# MSPM0G350X register map
Vendor: Texas Instruments; File version: This preliminary header file does not have a version number - build date: 2023-02-21 16:25:48
CPU: CM0 r0p1, little endian, MPU, no FPU, 3 interrupt priority bits
Registers are 32-bit, read-write, reset 0x0 unless marked. A register's access mark holds for its fields unless they carry their own. Offsets are from the block's base; [hi:lo] are bit positions; {n}, {i} and the like mark numbered series.

## GPIOB — PERIPHERALREGION
Base 0x400A2000
Same registers: GPIOA 0x400A0000
0x400 FSUB_0 — Subsciber Port 0
  [3:0] FSUB_0_CHANID — 0 = disconnected. 1-15 = connected to channelID = CHANID.
    0=FSUB_0_CHANID_UNCONNECTED (UNCONNECTED)
0x404 FSUB_1 — Subscriber Port 1
  [3:0] FSUB_1_CHANID — 0 = disconnected. 1-15 = connected to channelID = CHANID.
    0=FSUB_1_CHANID_UNCONNECTED (UNCONNECTED)
0x444 FPUB_0 — Publisher Port 0
  [3:0] FPUB_0_CHANID — 0 = disconnected. 1-15 = connected to channelID = CHANID.
    0=FPUB_0_CHANID_UNCONNECTED (UNCONNECTED)
0x448 FPUB_1 — Publisher Port 1
  [3:0] FPUB_1_CHANID — 0 = disconnected. 1-15 = connected to channelID = CHANID.
    0=FPUB_1_CHANID_UNCONNECTED (UNCONNECTED)
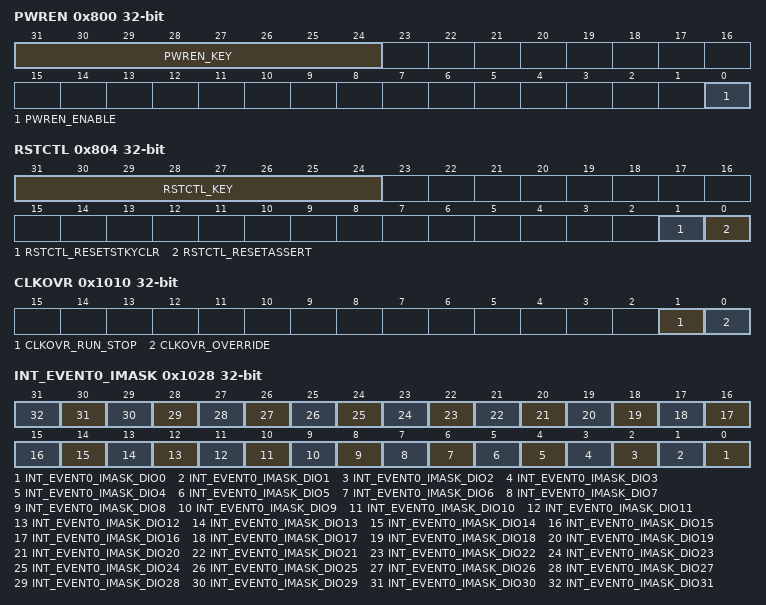
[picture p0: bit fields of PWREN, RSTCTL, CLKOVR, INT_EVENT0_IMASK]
0x800 PWREN — Power enable
  [31:24] PWREN_KEY wo — KEY to allow Power State Change
    38=PWREN_KEY_UNLOCK_W (_TO_UNLOCK_W_)
  [0] PWREN_ENABLE — Enable the power
    0=PWREN_ENABLE_DISABLE (DISABLE); 1=PWREN_ENABLE_ENABLE (ENABLE)
0x804 RSTCTL wo — Reset Control
  [31:24] RSTCTL_KEY — Unlock key
    177=RSTCTL_KEY_UNLOCK_W (_TO_UNLOCK_W_)
  [1] RSTCTL_RESETSTKYCLR — Clear the RESETSTKY bit in the STAT register
    0=RSTCTL_RESETSTKYCLR_NOP (NOP); 1=RSTCTL_RESETSTKYCLR_CLR (CLR)
  [0] RSTCTL_RESETASSERT — Assert reset to the peripheral
    0=RSTCTL_RESETASSERT_NOP (NOP); 1=RSTCTL_RESETASSERT_ASSERT (ASSERT)
0x814 STAT ro — Status Register
  [16] STAT_RESETSTKY — This bit indicates, if the peripheral was reset, since this bit was cleared by RESETSTKYCLR in the RSTCTL register
    0=STAT_RESETSTKY_NORES (NORES); 1=STAT_RESETSTKY_RESET (RESET)
0x1010 CLKOVR — Clock Override
  [1] CLKOVR_RUN_STOP — If [OVERRIDE] is enabled, this register is used to manually control the peripheral's clock request to the system
    0=CLKOVR_RUN_STOP_RUN (RUN); 1=CLKOVR_RUN_STOP_STOP (STOP)
  [0] CLKOVR_OVERRIDE — Unlocks the functionality of [RUN_STOP] to override the automatic peripheral clock request
    0=CLKOVR_OVERRIDE_DISABLED (DISABLED); 1=CLKOVR_OVERRIDE_ENABLED (ENABLED)
0x1018 PDBGCTL reset 0x1 — Peripheral Debug Control
  [0] PDBGCTL_FREE — Free run control
    0=PDBGCTL_FREE_STOP (STOP); 1=PDBGCTL_FREE_RUN (RUN)
0x1020 INT_EVENT0_IIDX ro — Interrupt index
  [7:0] INT_EVENT0_IIDX_STAT — Interrupt index status
    0=INT_EVENT0_IIDX_STAT_NO_INTR (NO_INTR); {v}=INT_EVENT0_IIDX_STAT_DIO{v-1} (DIO{v-1}) (v=1..32)
0x1028 INT_EVENT0_IMASK — Interrupt mask
  [n] INT_EVENT0_IMASK_DIO{n} (n=0..31) — DIO{n} event mask
    0=INT_EVENT0_IMASK_DIO{n}_CLR (CLR); 1=INT_EVENT0_IMASK_DIO{n}_SET (SET)
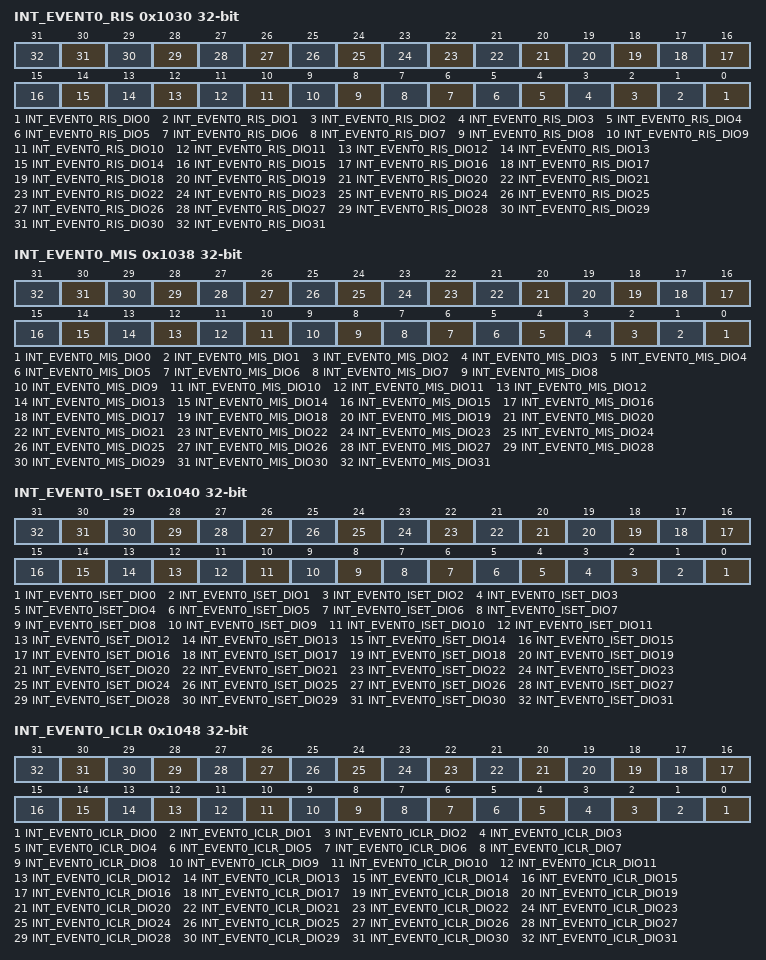
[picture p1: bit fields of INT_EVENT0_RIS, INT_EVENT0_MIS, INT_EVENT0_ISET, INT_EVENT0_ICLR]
0x1030 INT_EVENT0_RIS ro — Raw interrupt status
  [n] INT_EVENT0_RIS_DIO{n} (n=0..31) — DIO{n} event
    0=INT_EVENT0_RIS_DIO{n}_CLR (CLR); 1=INT_EVENT0_RIS_DIO{n}_SET (SET)
0x1038 INT_EVENT0_MIS ro — Masked interrupt status
  [n] INT_EVENT0_MIS_DIO{n} (n=0..31) — DIO{n} event
    0=INT_EVENT0_MIS_DIO{n}_CLR (CLR); 1=INT_EVENT0_MIS_DIO{n}_SET (SET)
0x1040 INT_EVENT0_ISET wo — Interrupt set
  [n] INT_EVENT0_ISET_DIO{n} (n=0..31) — DIO{n} event
    0=INT_EVENT0_ISET_DIO{n}_NO_EFFECT (NO_EFFECT); 1=INT_EVENT0_ISET_DIO{n}_SET (SET)
0x1048 INT_EVENT0_ICLR wo — Interrupt clear
  [n] INT_EVENT0_ICLR_DIO{n} (n=0..31) — DIO{n} event
    0=INT_EVENT0_ICLR_DIO{n}_NO_EFFECT (NO_EFFECT); 1=INT_EVENT0_ICLR_DIO{n}_CLR (CLR)
0x1050 INT_EVENT1_IIDX ro — Interrupt index
  [7:0] INT_EVENT1_IIDX_STAT — Interrupt index status
    0=INT_EVENT1_IIDX_STAT_NO_INTR (NO_INTR); {v}=INT_EVENT1_IIDX_STAT_DIO{v-1} (DIO{v-1}) (v=1..16)
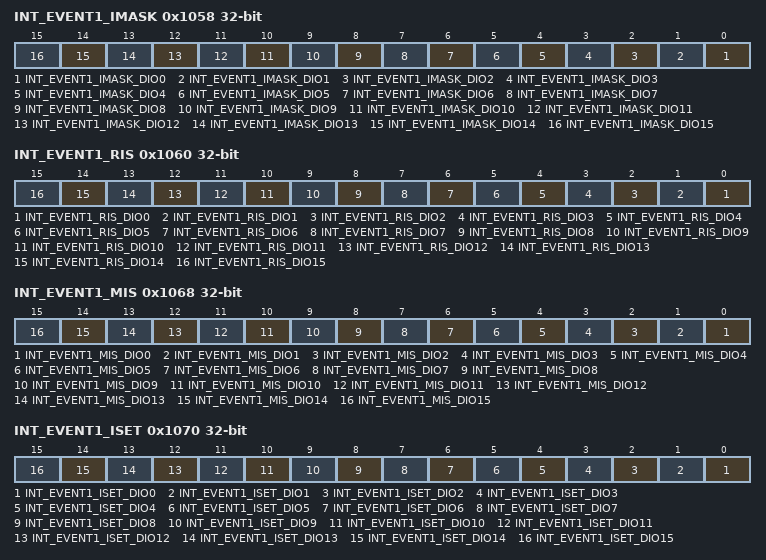
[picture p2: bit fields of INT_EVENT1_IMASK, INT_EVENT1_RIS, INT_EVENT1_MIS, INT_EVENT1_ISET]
0x1058 INT_EVENT1_IMASK — Interrupt mask
  [n] INT_EVENT1_IMASK_DIO{n} (n=0..15) — DIO{n} event mask
    0=INT_EVENT1_IMASK_DIO{n}_CLR (CLR); 1=INT_EVENT1_IMASK_DIO{n}_SET (SET)
0x1060 INT_EVENT1_RIS ro — Raw interrupt status
  [n] INT_EVENT1_RIS_DIO{n} (n=0..15) — DIO{n} event
    0=INT_EVENT1_RIS_DIO{n}_CLR (CLR); 1=INT_EVENT1_RIS_DIO{n}_SET (SET)
0x1068 INT_EVENT1_MIS ro — Masked interrupt status
  [n] INT_EVENT1_MIS_DIO{n} (n=0..15) — DIO{n} event
    0=INT_EVENT1_MIS_DIO{n}_CLR (CLR); 1=INT_EVENT1_MIS_DIO{n}_SET (SET)
0x1070 INT_EVENT1_ISET wo — Interrupt set
  [n] INT_EVENT1_ISET_DIO{n} (n=0..15) — DIO{n} event
    0=INT_EVENT1_ISET_DIO{n}_NO_EFFECT (NO_EFFECT); 1=INT_EVENT1_ISET_DIO{n}_SET (SET)
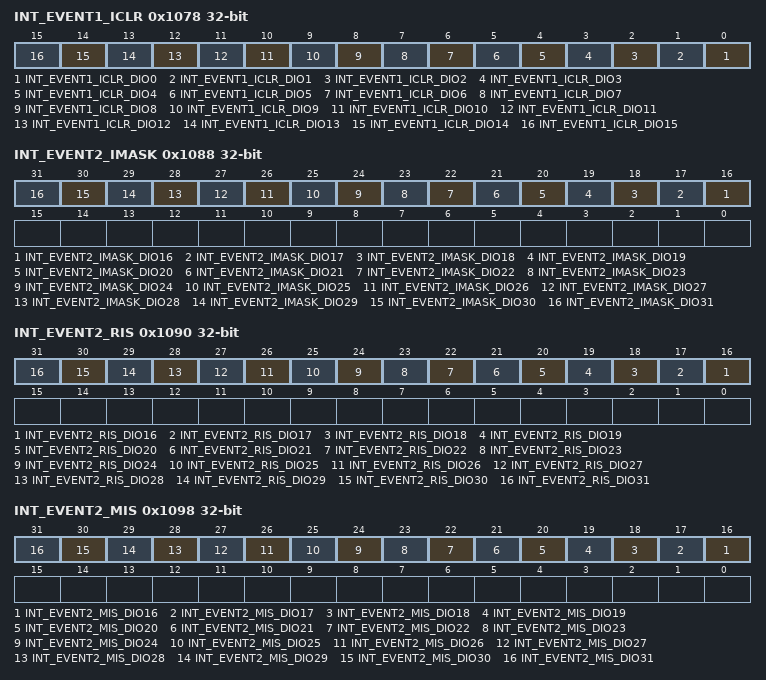
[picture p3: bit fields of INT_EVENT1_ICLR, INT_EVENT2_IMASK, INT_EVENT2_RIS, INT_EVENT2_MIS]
0x1078 INT_EVENT1_ICLR wo — Interrupt clear
  [n] INT_EVENT1_ICLR_DIO{n} (n=0..15) — DIO{n} event
    0=INT_EVENT1_ICLR_DIO{n}_NO_EFFECT (NO_EFFECT); 1=INT_EVENT1_ICLR_DIO{n}_CLR (CLR)
0x1080 INT_EVENT2_IIDX ro — Interrupt index
  [7:0] INT_EVENT2_IIDX_STAT — Interrupt index status
    0=INT_EVENT2_IIDX_STAT_NO_INTR (NO_INTR); {v}=INT_EVENT2_IIDX_STAT_DIO{v+15} (DIO{v+15}) (v=1..16)
0x1088 INT_EVENT2_IMASK — Interrupt mask
  [n] INT_EVENT2_IMASK_DIO{n} (n=16..31) — DIO{n} event mask
    0=INT_EVENT2_IMASK_DIO{n}_CLR (CLR); 1=INT_EVENT2_IMASK_DIO{n}_SET (SET)
0x1090 INT_EVENT2_RIS ro — Raw interrupt status
  [n] INT_EVENT2_RIS_DIO{n} (n=16..31) — DIO{n} event
    0=INT_EVENT2_RIS_DIO{n}_CLR (CLR); 1=INT_EVENT2_RIS_DIO{n}_SET (SET)
0x1098 INT_EVENT2_MIS ro — Masked interrupt status
  [n] INT_EVENT2_MIS_DIO{n} (n=16..31) — DIO{n} event
    0=INT_EVENT2_MIS_DIO{n}_CLR (CLR); 1=INT_EVENT2_MIS_DIO{n}_SET (SET)
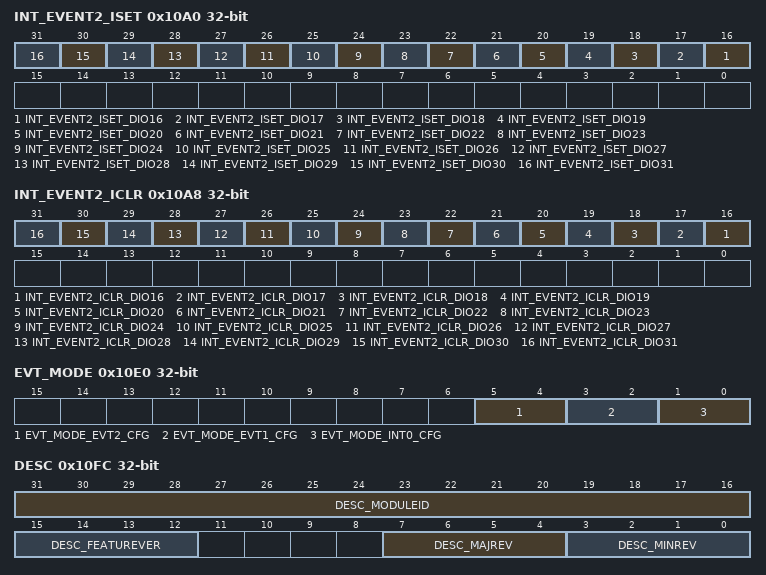
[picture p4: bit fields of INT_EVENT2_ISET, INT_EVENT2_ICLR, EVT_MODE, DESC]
0x10A0 INT_EVENT2_ISET wo — Interrupt set
  [n] INT_EVENT2_ISET_DIO{n} (n=16..31) — DIO{n} event
    0=INT_EVENT2_ISET_DIO{n}_NO_EFFECT (NO_EFFECT); 1=INT_EVENT2_ISET_DIO{n}_SET (SET)
0x10A8 INT_EVENT2_ICLR wo — Interrupt clear
  [n] INT_EVENT2_ICLR_DIO{n} (n=16..31) — DIO{n} event
    0=INT_EVENT2_ICLR_DIO{n}_NO_EFFECT (NO_EFFECT); 1=INT_EVENT2_ICLR_DIO{n}_CLR (CLR)
0x10E0 EVT_MODE — Event Mode
  [5:4] EVT_MODE_EVT2_CFG ro — Event line mode select for event corresponding to [IPSTANDARD.INT_EVENT2]
    0=EVT_MODE_EVT2_CFG_DISABLE (DISABLE); 1=EVT_MODE_EVT2_CFG_SOFTWARE (SOFTWARE); 2=EVT_MODE_EVT2_CFG_HARDWARE (HARDWARE)
  [3:2] EVT_MODE_EVT1_CFG ro — Event line mode select for event corresponding to [IPSTANDARD.INT_EVENT1]
    0=EVT_MODE_EVT1_CFG_DISABLE (DISABLE); 1=EVT_MODE_EVT1_CFG_SOFTWARE (SOFTWARE); 2=EVT_MODE_EVT1_CFG_HARDWARE (HARDWARE)
  [1:0] EVT_MODE_INT0_CFG ro — Event line mode select for event corresponding to [IPSTANDARD.INT_EVENT0]
    0=EVT_MODE_INT0_CFG_DISABLE (DISABLE); 1=EVT_MODE_INT0_CFG_SOFTWARE (SOFTWARE); 2=EVT_MODE_INT0_CFG_HARDWARE (HARDWARE)
0x10FC DESC ro — Module Description
  [31:16] DESC_MODULEID — Module identification contains a unique peripheral identification number. The assignments are maintained in a central database for all of the platform modules to ensure uniqueness.
  [15:12] DESC_FEATUREVER — Feature Set for the module *instance*
  [7:4] DESC_MAJREV — Major rev of the IP
  [3:0] DESC_MINREV — Minor rev of the IP
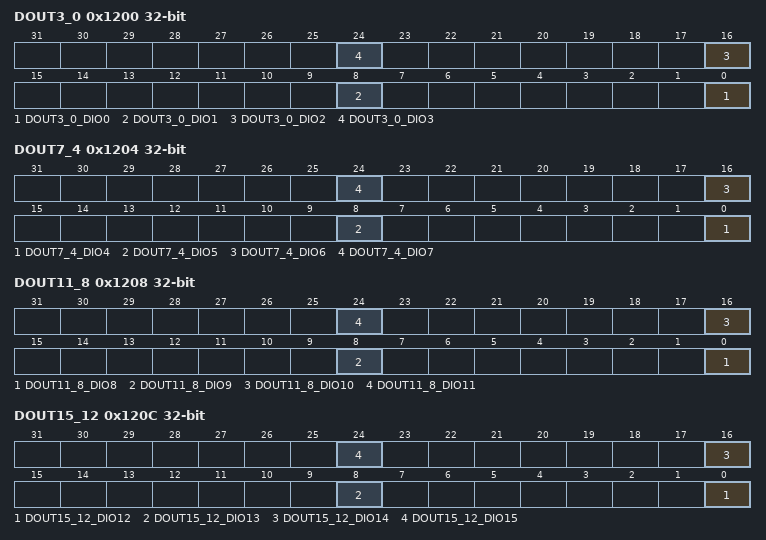
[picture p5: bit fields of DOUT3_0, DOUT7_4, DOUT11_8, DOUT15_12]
0x1200 DOUT3_0 wo — Data output 3 to 0
  [8n] DOUT3_0_DIO{n} (n=0..3) — This bit sets the value of the pin configured as DIO{n} when the output is enabled through DOE31_0 register.
    0=DOUT3_0_DIO{n}_ZERO (ZERO); 1=DOUT3_0_DIO{n}_ONE (ONE)
0x1204 DOUT7_4 wo — Data output 7 to 4
  [8n-32] DOUT7_4_DIO{n} (n=4..7) — This bit sets the value of the pin configured as DIO{n} when the output is enabled through DOE31_0 register.
    0=DOUT7_4_DIO{n}_ZERO (ZERO); 1=DOUT7_4_DIO{n}_ONE (ONE)
0x1208 DOUT11_8 wo — Data output 11 to 8
  [8n-64] DOUT11_8_DIO{n} (n=8..11) — This bit sets the value of the pin configured as DIO{n} when the output is enabled through DOE31_0 register.
    0=DOUT11_8_DIO{n}_ZERO (ZERO); 1=DOUT11_8_DIO{n}_ONE (ONE)
0x120C DOUT15_12 wo — Data output 15 to 12
  [8n-96] DOUT15_12_DIO{n} (n=12..15) — This bit sets the value of the pin configured as DIO{n} when the output is enabled through DOE31_0 register.
    0=DOUT15_12_DIO{n}_ZERO (ZERO); 1=DOUT15_12_DIO{n}_ONE (ONE)
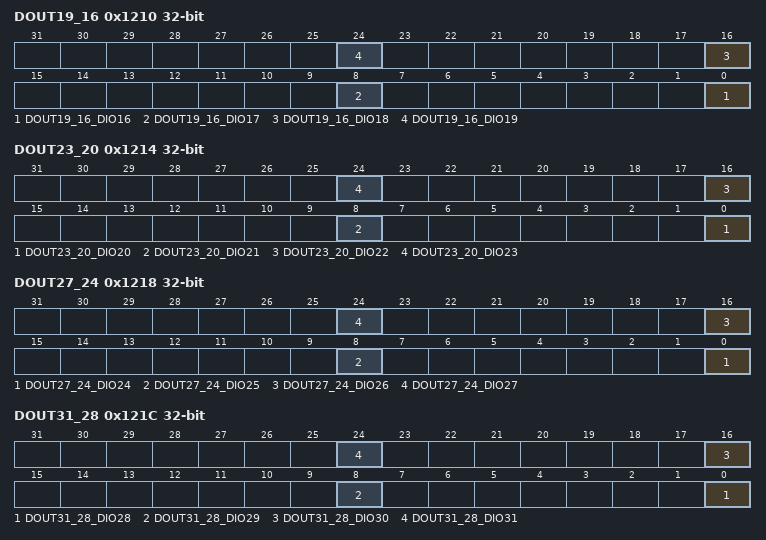
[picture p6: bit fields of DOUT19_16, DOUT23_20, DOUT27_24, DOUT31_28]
0x1210 DOUT19_16 wo — Data output 19 to 16
  [8n-128] DOUT19_16_DIO{n} (n=16..19) — This bit sets the value of the pin configured as DIO{n} when the output is enabled through DOE31_0 register.
    0=DOUT19_16_DIO{n}_ZERO (ZERO); 1=DOUT19_16_DIO{n}_ONE (ONE)
0x1214 DOUT23_20 wo — Data output 23 to 20
  [8n-160] DOUT23_20_DIO{n} (n=20..23) — This bit sets the value of the pin configured as DIO{n} when the output is enabled through DOE31_0 register.
    0=DOUT23_20_DIO{n}_ZERO (ZERO); 1=DOUT23_20_DIO{n}_ONE (ONE)
0x1218 DOUT27_24 wo — Data output 27 to 24
  [8n-192] DOUT27_24_DIO{n} (n=24..27) — This bit sets the value of the pin configured as DIO{n} when the output is enabled through DOE31_0 register.
    0=DOUT27_24_DIO{n}_ZERO (ZERO); 1=DOUT27_24_DIO{n}_ONE (ONE)
0x121C DOUT31_28 wo — Data output 31 to 28
  [8n-224] DOUT31_28_DIO{n} (n=28..31) — This bit sets the value of the pin configured as DIO{n} when the output is enabled through DOE31_0 register.
    0=DOUT31_28_DIO{n}_ZERO (ZERO); 1=DOUT31_28_DIO{n}_ONE (ONE)
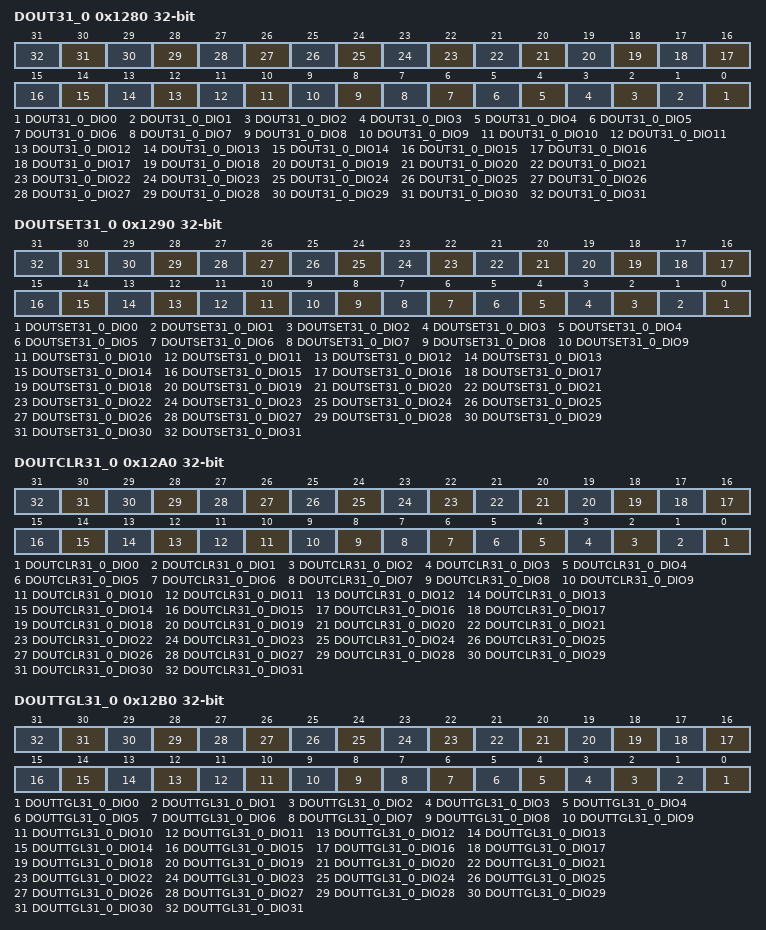
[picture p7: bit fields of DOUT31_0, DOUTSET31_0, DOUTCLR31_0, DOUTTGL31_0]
0x1280 DOUT31_0 — Data output 31 to 0
  [n] DOUT31_0_DIO{n} (n=0..31) — This bit sets the value of the pin configured as DIO{n} when the output is enabled through DOE31_0 register.
    0=DOUT31_0_DIO{n}_ZERO (ZERO); 1=DOUT31_0_DIO{n}_ONE (ONE)
0x1290 DOUTSET31_0 wo — Data output set 31 to 0
  [n] DOUTSET31_0_DIO{n} (n=0..31) — Writing 1 to this bit sets the DIO{n} bit in the DOUT31_0 register. Writing 0 has no effect.
    0=DOUTSET31_0_DIO{n}_NO_EFFECT (NO_EFFECT); 1=DOUTSET31_0_DIO{n}_SET (SET)
0x12A0 DOUTCLR31_0 wo — Data output clear 31 to 0
  [n] DOUTCLR31_0_DIO{n} (n=0..31) — Writing 1 to this bit clears the DIO{n} bit in the DOUT31_0 register. Writing 0 has no effect.
    0=DOUTCLR31_0_DIO{n}_NO_EFFECT (NO_EFFECT); 1=DOUTCLR31_0_DIO{n}_CLR (CLR)
0x12B0 DOUTTGL31_0 wo — Data output toggle 31 to 0
  [n] DOUTTGL31_0_DIO{n} (n=0..31) — This bit is used to toggle DIO{n} output.
    0=DOUTTGL31_0_DIO{n}_NO_EFFECT (NO_EFFECT); 1=DOUTTGL31_0_DIO{n}_TOGGLE (TOGGLE)
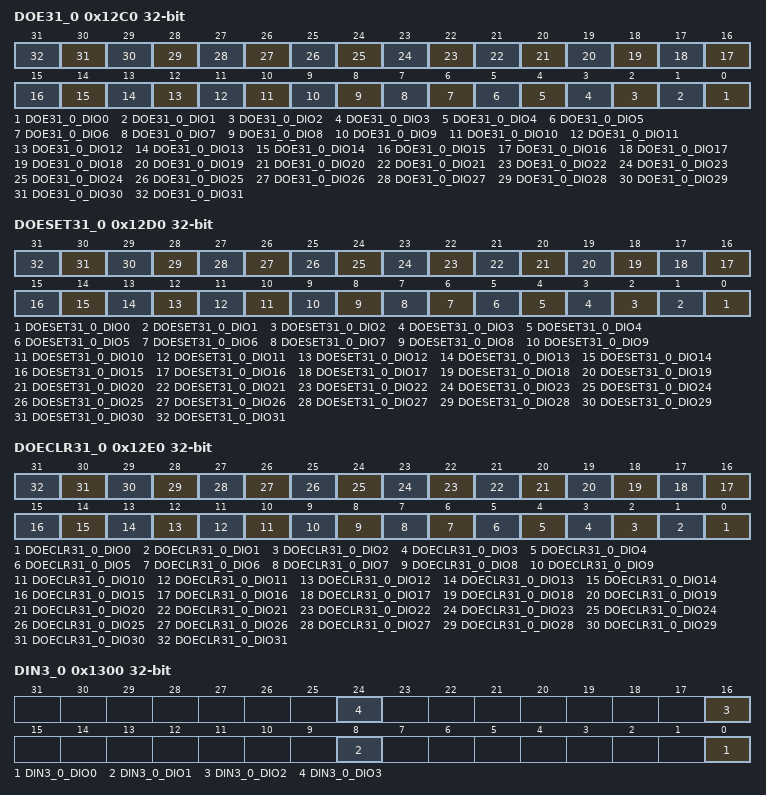
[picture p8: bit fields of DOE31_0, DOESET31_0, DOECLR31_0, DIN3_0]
0x12C0 DOE31_0 — Data output enable 31 to 0
  [n] DOE31_0_DIO{n} (n=0..31) — Enables data output for DIO{n}.
    0=DOE31_0_DIO{n}_DISABLE (DISABLE); 1=DOE31_0_DIO{n}_ENABLE (ENABLE)
0x12D0 DOESET31_0 wo — Data output enable set 31 to 0
  [n] DOESET31_0_DIO{n} (n=0..31) — Writing 1 to this bit sets the DIO{n} bit in the DOE31_0 register. Writing 0 has no effect.
    0=DOESET31_0_DIO{n}_NO_EFFECT (NO_EFFECT); 1=DOESET31_0_DIO{n}_SET (SET)
0x12E0 DOECLR31_0 wo — Data output enable clear 31 to 0
  [n] DOECLR31_0_DIO{n} (n=0..31) — Writing 1 to this bit clears the DIO{n} bit in the DOE31_0 register. Writing 0 has no effect.
    0=DOECLR31_0_DIO{n}_NO_EFFECT (NO_EFFECT); 1=DOECLR31_0_DIO{n}_CLR (CLR)
0x1300 DIN3_0 ro — Data input 3 to 0
  [8n] DIN3_0_DIO{n} (n=0..3) — This bit reads the data input value of DIO{n}.
    0=DIN3_0_DIO{n}_ZERO (ZERO); 1=DIN3_0_DIO{n}_ONE (ONE)
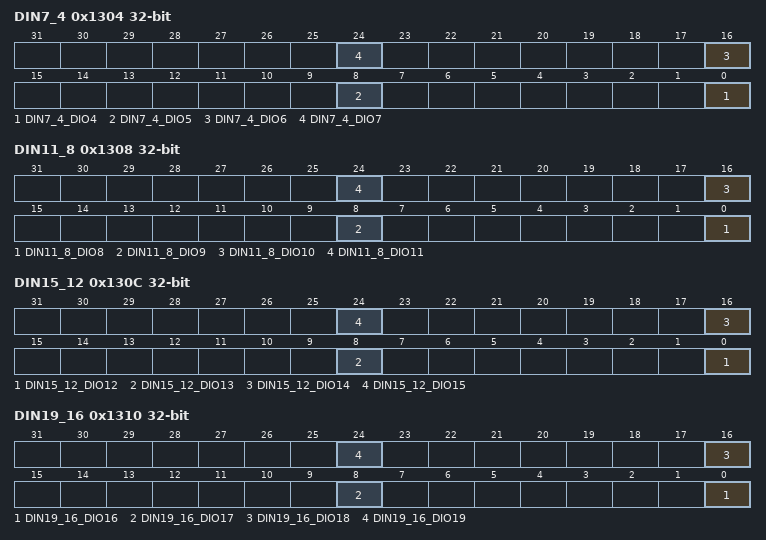
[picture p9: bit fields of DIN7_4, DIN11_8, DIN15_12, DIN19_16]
0x1304 DIN7_4 ro — Data input 7 to 4
  [8n-32] DIN7_4_DIO{n} (n=4..7) — This bit reads the data input value of DIO{n}.
    0=DIN7_4_DIO{n}_ZERO (ZERO); 1=DIN7_4_DIO{n}_ONE (ONE)
0x1308 DIN11_8 ro — Data input 11 to 8
  [8n-64] DIN11_8_DIO{n} (n=8..11) — This bit reads the data input value of DIO{n}.
    0=DIN11_8_DIO{n}_ZERO (ZERO); 1=DIN11_8_DIO{n}_ONE (ONE)
0x130C DIN15_12 ro — Data input 15 to 12
  [8n-96] DIN15_12_DIO{n} (n=12..15) — This bit reads the data input value of DIO{n}.
    0=DIN15_12_DIO{n}_ZERO (ZERO); 1=DIN15_12_DIO{n}_ONE (ONE)
0x1310 DIN19_16 ro — Data input 19 to 16
  [8n-128] DIN19_16_DIO{n} (n=16..19) — This bit reads the data input value of DIO{n}.
    0=DIN19_16_DIO{n}_ZERO (ZERO); 1=DIN19_16_DIO{n}_ONE (ONE)
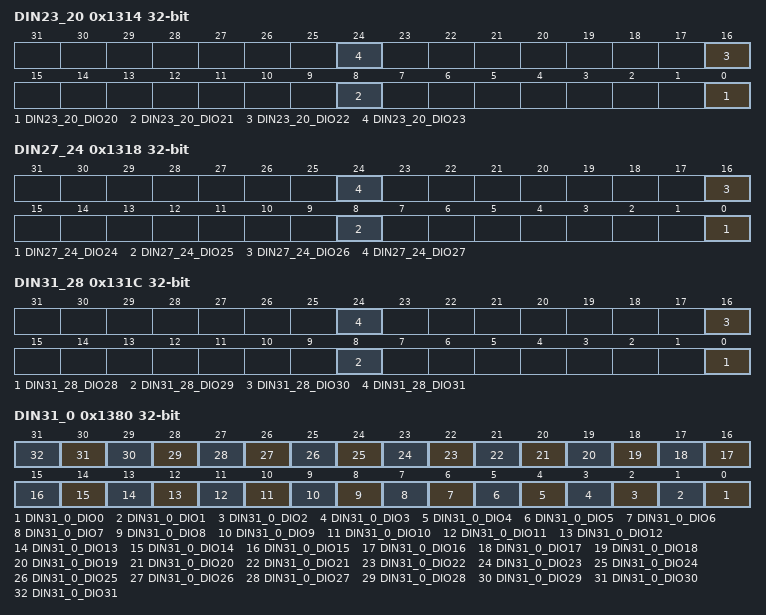
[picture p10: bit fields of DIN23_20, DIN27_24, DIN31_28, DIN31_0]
0x1314 DIN23_20 ro — Data input 23 to 20
  [8n-160] DIN23_20_DIO{n} (n=20..23) — This bit reads the data input value of DIO{n}.
    0=DIN23_20_DIO{n}_ZERO (ZERO); 1=DIN23_20_DIO{n}_ONE (ONE)
0x1318 DIN27_24 ro — Data input 27 to 24
  [8n-192] DIN27_24_DIO{n} (n=24..27) — This bit reads the data input value of DIO{n}.
    0=DIN27_24_DIO{n}_ZERO (ZERO); 1=DIN27_24_DIO{n}_ONE (ONE)
0x131C DIN31_28 ro — Data input 31 to 28
  [8n-224] DIN31_28_DIO{n} (n=28..31) — This bit reads the data input value of DIO{n}.
    0=DIN31_28_DIO{n}_ZERO (ZERO); 1=DIN31_28_DIO{n}_ONE (ONE)
0x1380 DIN31_0 ro — Data input 31 to 0
  [n] DIN31_0_DIO{n} (n=0..31) — This bit reads the data input value of DIO{n}.
    0=DIN31_0_DIO{n}_ZERO (ZERO); 1=DIN31_0_DIO{n}_ONE (ONE)
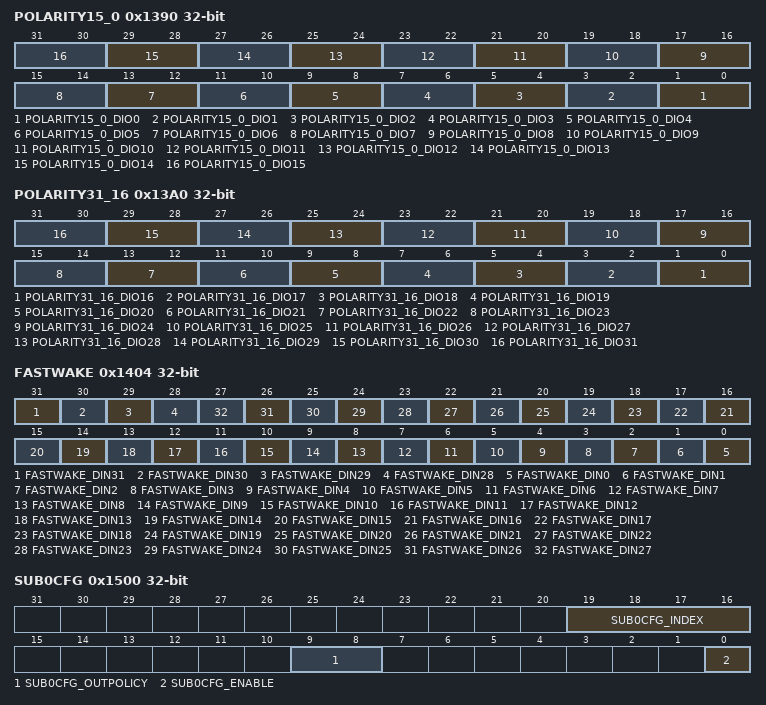
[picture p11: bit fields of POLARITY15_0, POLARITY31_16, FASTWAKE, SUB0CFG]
0x1390 POLARITY15_0 — Polarity 15 to 0
  [2n+1:2n] POLARITY15_0_DIO{n} (n=0..15) — Enables and configures edge detection polarity for DIO{n}.
    0=POLARITY15_0_DIO{n}_DISABLE (DISABLE); 1=POLARITY15_0_DIO{n}_RISE (RISE); 2=POLARITY15_0_DIO{n}_FALL (FALL); 3=POLARITY15_0_DIO{n}_RISE_FALL (RISE_FALL)
0x13A0 POLARITY31_16 — Polarity 31 to 16
  [2n-31:2n-32] POLARITY31_16_DIO{n} (n=16..31) — Enables and configures edge detection polarity for DIO{n}.
    0=POLARITY31_16_DIO{n}_DISABLE (DISABLE); 1=POLARITY31_16_DIO{n}_RISE (RISE); 2=POLARITY31_16_DIO{n}_FALL (FALL); 3=POLARITY31_16_DIO{n}_RISE_FALL (RISE_FALL)
0x1400 CTL — FAST WAKE GLOBAL EN
  [0] CTL_FASTWAKEONLY — FASTWAKEONLY for the global control of fastwake
    0=CTL_FASTWAKEONLY_NOT_GLOBAL_EN (NOT_GLOBAL_EN); 1=CTL_FASTWAKEONLY_GLOBAL_EN (GLOBAL_EN)
0x1404 FASTWAKE — FAST WAKE ENABLE
  [31] FASTWAKE_DIN31 — Enable fastwake feature for DIN31
    0=FASTWAKE_DIN31_DISABLE (DISABLE); 1=FASTWAKE_DIN31_ENABLE (ENABLE)
  [30] FASTWAKE_DIN30 — Enable fastwake feature for DIN30
    0=FASTWAKE_DIN30_DISABLE (DISABLE); 1=FASTWAKE_DIN30_ENABLE (ENABLE)
  [29] FASTWAKE_DIN29 — Enable fastwake feature for DIN29
    0=FASTWAKE_DIN29_DISABLE (DISABLE); 1=FASTWAKE_DIN29_ENABLE (ENABLE)
  [28] FASTWAKE_DIN28 — Enable fastwake feature for DIN29
    0=FASTWAKE_DIN28_DISABLE (DISABLE); 1=FASTWAKE_DIN28_ENABLE (ENABLE)
  [n] FASTWAKE_DIN{n} (n=0..27) — Enable fastwake feature for DIN{n}
    0=FASTWAKE_DIN{n}_DISABLE (DISABLE); 1=FASTWAKE_DIN{n}_ENABLE (ENABLE)
0x1500 SUB0CFG — Subscriber 0 configuration
  [19:16] SUB0CFG_INDEX — Indicates the specific bit among lower 16 bits that is targeted by the subscriber action
    0=SUB0CFG_INDEX_MIN (MIN); 15=SUB0CFG_INDEX_MAX (MAX)
  [9:8] SUB0CFG_OUTPOLICY — These bits configure the output policy for subscriber 0 event.
    0=SUB0CFG_OUTPOLICY_SET (SET); 1=SUB0CFG_OUTPOLICY_CLR (CLR); 2=SUB0CFG_OUTPOLICY_TOGGLE (TOGGLE)
  [0] SUB0CFG_ENABLE — This bit is used to enable subscriber 0 event.
    0=SUB0CFG_ENABLE_CLR (CLR); 1=SUB0CFG_ENABLE_SET (SET)
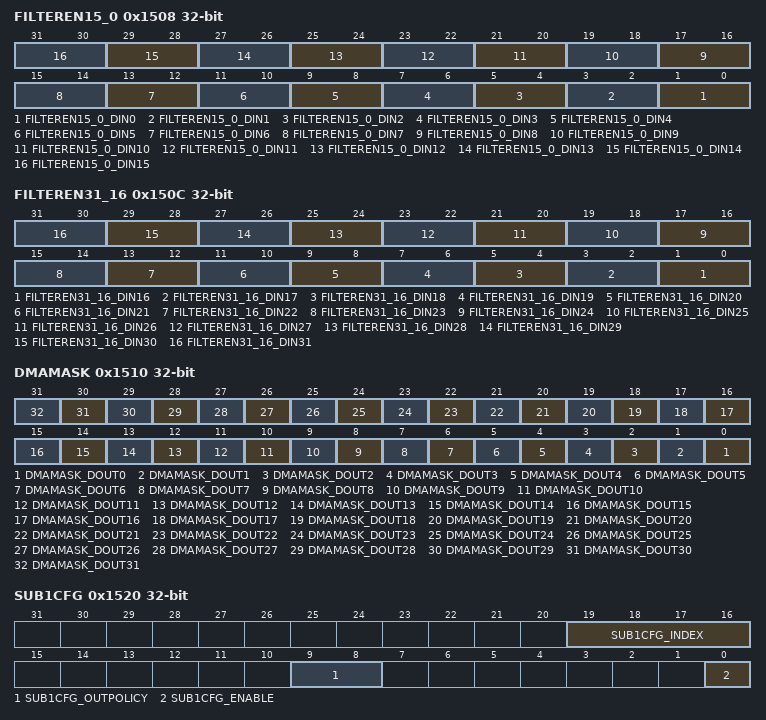
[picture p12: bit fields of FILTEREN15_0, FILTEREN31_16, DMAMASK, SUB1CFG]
0x1508 FILTEREN15_0 — Filter Enable 15 to 0
  [2n+1:2n] FILTEREN15_0_DIN{n} (n=0..15) — Programmable counter length of digital glitch filter for DIN{n}
    0=FILTEREN15_0_DIN{n}_DISABLE (DISABLE); 1=FILTEREN15_0_DIN{n}_ONE_CYCLE (ONE_CYCLE); 2=FILTEREN15_0_DIN{n}_THREE_CYCLE (THREE_CYCLE); 3=FILTEREN15_0_DIN{n}_EIGHT_CYCLE (EIGHT_CYCLE)
0x150C FILTEREN31_16 — Filter Enable 31 to 16
  [2n-31:2n-32] FILTEREN31_16_DIN{n} (n=16..31) — Programmable counter length of digital glitch filter for DIN{n}
    0=FILTEREN31_16_DIN{n}_DISABLE (DISABLE); 1=FILTEREN31_16_DIN{n}_ONE_CYCLE (ONE_CYCLE); 2=FILTEREN31_16_DIN{n}_THREE_CYCLE (THREE_CYCLE); 3=FILTEREN31_16_DIN{n}_EIGHT_CYCLE (EIGHT_CYCLE)
0x1510 DMAMASK — DMA Write MASK
  [n] DMAMASK_DOUT{n} (n=0..31) — DMA is allowed to modify DOUT{n}
    0=DMAMASK_DOUT{n}_DISABLE (DISABLE); 1=DMAMASK_DOUT{n}_ENABLE (ENABLE)
0x1520 SUB1CFG — Subscriber 1 configuration
  [19:16] SUB1CFG_INDEX — indicates the specific bit in the upper 16 bits that is targeted by the subscriber action
    0=SUB1CFG_INDEX_MIN (MIN); 15=SUB1CFG_INDEX_MAX (MAX)
  [9:8] SUB1CFG_OUTPOLICY — These bits configure the output policy for subscriber 1 event.
    0=SUB1CFG_OUTPOLICY_SET (SET); 1=SUB1CFG_OUTPOLICY_CLR (CLR); 2=SUB1CFG_OUTPOLICY_TOGGLE (TOGGLE)
  [0] SUB1CFG_ENABLE — This bit is used to enable subscriber 1 event.
    0=SUB1CFG_ENABLE_CLR (CLR); 1=SUB1CFG_ENABLE_SET (SET)
